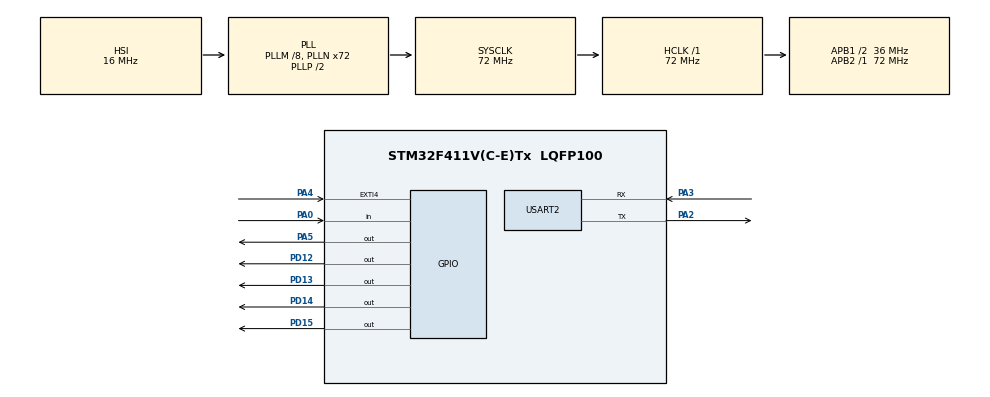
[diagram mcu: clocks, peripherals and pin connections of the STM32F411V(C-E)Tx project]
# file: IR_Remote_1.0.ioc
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Mcu.Family=STM32F4
Mcu.Name=STM32F411V(C-E)Tx
Mcu.Package=LQFP100
NVIC.EXTI4_IRQn=true\:0\:0\:false\:false\:true\:true\:true\:true
NVIC.PriorityGroup=NVIC_PRIORITYGROUP_4
NVIC.TIM2_IRQn=true\:0\:0\:false\:false\:true\:true\:true\:true
NVIC.USART2_IRQn=true\:0\:0\:false\:false\:true\:true\:true\:true
PA0-WKUP.Signal=GPIO_Input
PA13.Mode=Serial_Wire
PA13.Signal=SYS_JTMS-SWDIO
PA14.Mode=Serial_Wire
PA14.Signal=SYS_JTCK-SWCLK
PA2.Mode=Asynchronous
PA2.Signal=USART2_TX
PA3.Mode=Asynchronous
PA3.Signal=USART2_RX
PA4.GPIO_ModeDefaultEXTI=GPIO_MODE_IT_FALLING
PA4.Signal=GPXTI4
PA5.Signal=GPIO_Output
PD12.Signal=GPIO_Output
PD13.Signal=GPIO_Output
PD14.Signal=GPIO_Output
PD15.Signal=GPIO_Output
ProjectManager.HeapSize=0x200
ProjectManager.StackSize=0x400
ProjectManager.TargetToolchain=STM32CubeIDE
RCC.48MHZClocksFreq_Value=36000000
RCC.AHBFreq_Value=72000000
RCC.APB1CLKDivider=RCC_HCLK_DIV2
RCC.APB1Freq_Value=36000000
RCC.APB1TimFreq_Value=72000000
RCC.APB2Freq_Value=72000000
RCC.APB2TimFreq_Value=72000000
RCC.CortexFreq_Value=72000000
RCC.HCLKFreq_Value=72000000
RCC.HSE_VALUE=25000000
RCC.HSI_VALUE=16000000
RCC.LSE_VALUE=32768
RCC.PLLM=8
RCC.PLLN=72
RCC.SYSCLKFreq_VALUE=72000000
RCC.SYSCLKSource=RCC_SYSCLKSOURCE_PLLCLK
RCC.VCOOutputFreq_Value=144000000
TIM2.Prescaler=30
USART2.VirtualMode=VM_ASYNC
VP_TIM2_VS_ClockSourceINT.Mode=Internal
board=custom

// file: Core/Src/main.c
/* USER CODE BEGIN Header */
/**
  ******************************************************************************
  * @file           : main.c
  * @brief          : Main program body
  ******************************************************************************
  * @attention
  *
  * Copyright (c) 2023 STMicroelectronics.
  * All rights reserved.
  *
  * This software is licensed under terms that can be found in the LICENSE file
  * in the root directory of this software component.
  * If no LICENSE file comes with this software, it is provided AS-IS.
  *
  ******************************************************************************
  */
/* USER CODE END Header */
#include "main.h"

/* USER CODE BEGIN Includes */

#include <stdio.h>
#include <string.h>
#include "IR_Remote.h"

/* USER CODE END Includes */

TIM_HandleTypeDef htim2;

UART_HandleTypeDef huart2;

void SystemClock_Config(void);
static void MX_GPIO_Init(void);
static void MX_USART2_UART_Init(void);
static void MX_TIM2_Init(void);

/* USER CODE BEGIN 0 */

IR_DATA_t ir_remote;

void HAL_GPIO_EXTI_Callback(uint16_t GPIO_Pin)
{
	IR_REMOTE_EXTI_Handle(&ir_remote);
}

void HAL_TIM_PeriodElapsedCallback(TIM_HandleTypeDef *htim)
{
	IR_REMOTE_TIMI_Handle(&ir_remote, htim);
}

void IR_REMOTE_RxCpltCallback(DECODED_DATA_t *decode_value)
{
	char temp_str[30];
	sprintf(temp_str, "Add:0x%02X - Cmd:0x%02X\n", decode_value->value.NEC.address, decode_value->value.NEC.command);
	HAL_UART_Transmit_IT(&huart2, (uint8_t *)temp_str, strlen(temp_str));
}

/* USER CODE END 0 */

int main(void)
{

  /* MCU Configuration--------------------------------------------------------*/

  /* Reset of all peripherals, Initializes the Flash interface and the Systick. */
  HAL_Init();

  /* Configure the system clock */
  SystemClock_Config();

  /* Initialize all configured peripherals */
  MX_GPIO_Init();
  MX_USART2_UART_Init();
  MX_TIM2_Init();
  /* USER CODE BEGIN 2 */

  IR_REMOTE_Init(&ir_remote, GPIOA, GPIO_PIN_4, &htim2, DECODE_TYPE_NEC);
//  htim2.Instance->CNT = -100;
//  HAL_TIM_Base_Start_IT(&htim2);

  /* USER CODE END 2 */

  /* Infinite loop */
  while (1)
  {

    /* USER CODE BEGIN 3 */

//	  IR_REMOTE_Handle(&ir_remote);

  }
  /* USER CODE END 3 */
}

void SystemClock_Config(void)
{
  RCC_OscInitTypeDef RCC_OscInitStruct = {0};
  RCC_ClkInitTypeDef RCC_ClkInitStruct = {0};

  /** Configure the main internal regulator output voltage
  */
  __HAL_RCC_PWR_CLK_ENABLE();
  __HAL_PWR_VOLTAGESCALING_CONFIG(PWR_REGULATOR_VOLTAGE_SCALE1);

  /** Initializes the RCC Oscillators according to the specified parameters
  * in the RCC_OscInitTypeDef structure.
  */
  RCC_OscInitStruct.OscillatorType = RCC_OSCILLATORTYPE_HSI;
  RCC_OscInitStruct.HSIState = RCC_HSI_ON;
  RCC_OscInitStruct.HSICalibrationValue = RCC_HSICALIBRATION_DEFAULT;
  RCC_OscInitStruct.PLL.PLLState = RCC_PLL_ON;
  RCC_OscInitStruct.PLL.PLLSource = RCC_PLLSOURCE_HSI;
  RCC_OscInitStruct.PLL.PLLM = 8;
  RCC_OscInitStruct.PLL.PLLN = 72;
  RCC_OscInitStruct.PLL.PLLP = RCC_PLLP_DIV2;
  RCC_OscInitStruct.PLL.PLLQ = 4;
  if (HAL_RCC_OscConfig(&RCC_OscInitStruct) != HAL_OK)
  {
    Error_Handler();
  }

  /** Initializes the CPU, AHB and APB buses clocks
  */
  RCC_ClkInitStruct.ClockType = RCC_CLOCKTYPE_HCLK|RCC_CLOCKTYPE_SYSCLK
                              |RCC_CLOCKTYPE_PCLK1|RCC_CLOCKTYPE_PCLK2;
  RCC_ClkInitStruct.SYSCLKSource = RCC_SYSCLKSOURCE_PLLCLK;
  RCC_ClkInitStruct.AHBCLKDivider = RCC_SYSCLK_DIV1;
  RCC_ClkInitStruct.APB1CLKDivider = RCC_HCLK_DIV2;
  RCC_ClkInitStruct.APB2CLKDivider = RCC_HCLK_DIV1;

  if (HAL_RCC_ClockConfig(&RCC_ClkInitStruct, FLASH_LATENCY_2) != HAL_OK)
  {
    Error_Handler();
  }
}

static void MX_TIM2_Init(void)
{

  TIM_ClockConfigTypeDef sClockSourceConfig = {0};
  TIM_MasterConfigTypeDef sMasterConfig = {0};

  htim2.Instance = TIM2;
  htim2.Init.Prescaler = 30;
  htim2.Init.CounterMode = TIM_COUNTERMODE_UP;
  htim2.Init.Period = 4294967295;
  htim2.Init.ClockDivision = TIM_CLOCKDIVISION_DIV1;
  htim2.Init.AutoReloadPreload = TIM_AUTORELOAD_PRELOAD_DISABLE;
  if (HAL_TIM_Base_Init(&htim2) != HAL_OK)
  {
    Error_Handler();
  }
  sClockSourceConfig.ClockSource = TIM_CLOCKSOURCE_INTERNAL;
  if (HAL_TIM_ConfigClockSource(&htim2, &sClockSourceConfig) != HAL_OK)
  {
    Error_Handler();
  }
  sMasterConfig.MasterOutputTrigger = TIM_TRGO_RESET;
  sMasterConfig.MasterSlaveMode = TIM_MASTERSLAVEMODE_DISABLE;
  if (HAL_TIMEx_MasterConfigSynchronization(&htim2, &sMasterConfig) != HAL_OK)
  {
    Error_Handler();
  }

}

static void MX_USART2_UART_Init(void)
{

  huart2.Instance = USART2;
  huart2.Init.BaudRate = 115200;
  huart2.Init.WordLength = UART_WORDLENGTH_8B;
  huart2.Init.StopBits = UART_STOPBITS_1;
  huart2.Init.Parity = UART_PARITY_NONE;
  huart2.Init.Mode = UART_MODE_TX_RX;
  huart2.Init.HwFlowCtl = UART_HWCONTROL_NONE;
  huart2.Init.OverSampling = UART_OVERSAMPLING_16;
  if (HAL_UART_Init(&huart2) != HAL_OK)
  {
    Error_Handler();
  }

}

static void MX_GPIO_Init(void)
{
  GPIO_InitTypeDef GPIO_InitStruct = {0};

  /* GPIO Ports Clock Enable */
  __HAL_RCC_GPIOA_CLK_ENABLE();
  __HAL_RCC_GPIOD_CLK_ENABLE();

  /*Configure GPIO pin Output Level */
  HAL_GPIO_WritePin(GPIOA, GPIO_PIN_5, GPIO_PIN_RESET);

  /*Configure GPIO pin Output Level */
  HAL_GPIO_WritePin(GPIOD, GPIO_PIN_12|GPIO_PIN_13|GPIO_PIN_14|GPIO_PIN_15, GPIO_PIN_RESET);

  /*Configure GPIO pin : PA0 */
  GPIO_InitStruct.Pin = GPIO_PIN_0;
  GPIO_InitStruct.Mode = GPIO_MODE_INPUT;
  GPIO_InitStruct.Pull = GPIO_NOPULL;
  HAL_GPIO_Init(GPIOA, &GPIO_InitStruct);

  /*Configure GPIO pin : PA4 */
  GPIO_InitStruct.Pin = GPIO_PIN_4;
  GPIO_InitStruct.Mode = GPIO_MODE_IT_FALLING;
  GPIO_InitStruct.Pull = GPIO_NOPULL;
  HAL_GPIO_Init(GPIOA, &GPIO_InitStruct);

  /*Configure GPIO pin : PA5 */
  GPIO_InitStruct.Pin = GPIO_PIN_5;
  GPIO_InitStruct.Mode = GPIO_MODE_OUTPUT_PP;
  GPIO_InitStruct.Pull = GPIO_NOPULL;
  GPIO_InitStruct.Speed = GPIO_SPEED_FREQ_LOW;
  HAL_GPIO_Init(GPIOA, &GPIO_InitStruct);

  /*Configure GPIO pins : PD12 PD13 PD14 PD15 */
  GPIO_InitStruct.Pin = GPIO_PIN_12|GPIO_PIN_13|GPIO_PIN_14|GPIO_PIN_15;
  GPIO_InitStruct.Mode = GPIO_MODE_OUTPUT_PP;
  GPIO_InitStruct.Pull = GPIO_NOPULL;
  GPIO_InitStruct.Speed = GPIO_SPEED_FREQ_LOW;
  HAL_GPIO_Init(GPIOD, &GPIO_InitStruct);

  /* EXTI interrupt init*/
  HAL_NVIC_SetPriority(EXTI4_IRQn, 0, 0);
  HAL_NVIC_EnableIRQ(EXTI4_IRQn);

}

void Error_Handler(void)
{
  __disable_irq();
  while (1)
  {
  }
}
